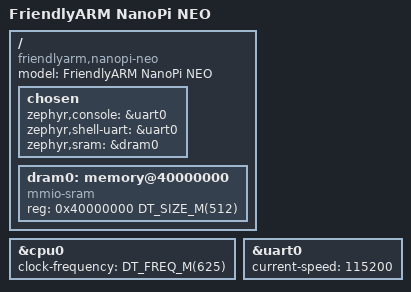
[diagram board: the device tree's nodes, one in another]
/*
 * Copyright The Zephyr Project Contributors
 *
 * SPDX-License-Identifier: Apache-2.0
 */

/dts-v1/;

#include <allwinner/sun8i-h3.dtsi>

/ {
	compatible = "friendlyarm,nanopi-neo", "allwinner,sun8i-h3";
	model = "FriendlyARM NanoPi NEO";

	chosen {
		zephyr,console = &uart0;
		zephyr,shell-uart = &uart0;
		zephyr,sram = &dram0;
	};

	dram0: memory@40000000 {
		compatible = "mmio-sram";
		reg = <0x40000000 DT_SIZE_M(512)>;
		device_type = "memory";
	};
};

&cpu0 {
	clock-frequency = <DT_FREQ_M(625)>;
};

&uart0 {
	current-speed = <115200>;
	status = "okay";
};
